# RK3399-M0 register map
File version: 1
CPU: CM0 r0p1, little endian, no MPU, no FPU, 4 interrupt priority bits, 32 interrupts
Registers are 32-bit, read-write, reset 0x0 unless marked. A register's access mark holds for its fields unless they carry their own. Offsets are from the block's base; [hi:lo] are bit positions; {n}, {i} and the like mark numbered series.

## MSCH0
Base 0x47A84000
Same registers: MSCH1 0x47A8C000
0x00 MSCH_Id_CoreId access not given reset 0xD867004 — Core ID register
0x04 MSCH_Id_RevisionId access not given reset 0x1AA00 — Revision ID register
0x08 MSCH_DeviceConf access not given — ddr configuration pointers
0x0C MSCH_DeviceSize access not given — ddr configuration sizes.
0x10 MSCH_DdrTimingA0 access not given reset 0x28140916 — DdrTimingA bank 0
0x14 MSCH_DdrTimingB0 access not given reset 0x40702 — DdrTimingB bank 0
0x18 MSCH_DdrTimingC0 access not given reset 0x2 — DdrTimingC bank 0
0x1C MSCH_DevToDev0 access not given reset 0x222 — Timing values concerning device to device data bus ownership c
0x110 MSCH_DdrMode access not given reset 0x4C — ddr mode definition.
0x1000 MSCH_AgingX0 access not given — Aging threshold multiplicator.

## SARADC
Base 0x47100000
0x00 SARADC_DATA ro — This register contains the data after A/D Conversion.
  [9:0] ADC_DATA — A/D value of the last conversion (DOUT[9:0]).
0x04 SARADC_STAS ro — The status register of A/D Converter.
  [0] ADC_STATUS — ADC status (EOC) 0: ADC stop 1: Conversion in progress
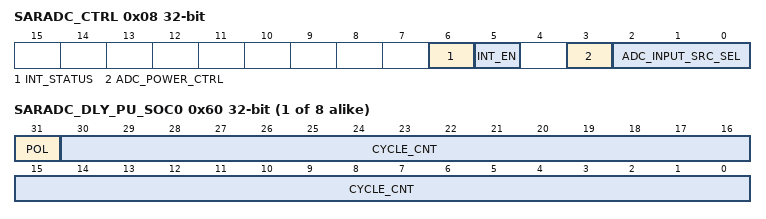
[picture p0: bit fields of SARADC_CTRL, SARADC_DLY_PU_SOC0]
0x08 SARADC_CTRL — The control register of A/D Converter.
  [6] INT_STATUS — Interrupt status. This bit will be set to 1 when end-of-conversion. Set 0 to clear the interrupt.
  [5] INT_EN — Interrupt enable. 0: Disable 1: Enable
  [3] ADC_POWER_CTRL — ADC power down control bit 0: ADC power down; 1: ADC power up and reset. start signal will be asserted (DLY_PU_SOC + 2) sclk clock period later after power up
  [2:0] ADC_INPUT_SRC_SEL — ADC input source selection(CH_SEL[2:0]). 000 : Input source 0 (SARADC_AIN[0]) 001 : Input source 1 (SARADC_AIN[1]) 010 : Input source 2 (SARADC_AIN[2]) 011 : Input source 3 (SARADC_AIN[3]) 100 : Input source 4 (SARADC_AIN[4]) 101 : Input source 5 (SARADC_AIN[5]) Others : Reserved
0x0C SARADC_DLY_PU_SOC — delay between power up and start command
  [5:0] DLY_PU_SOC — delay between power up and start command The start signal will be asserted (DLY_PU_SOC + 2) sclk clock period later after power up
{0x60+4i} SARADC_DLY_PU_SOC{i} access per field (i=0..7) — FIFO Register
  [31] POL rw — Polarity This bit indicates the polarity of the lower 31-bit counter. 0: Low 1: High
  [30:0] CYCLE_CNT ro — High/Low Cycle Counter This 31-bit counter indicates the effective cycles of high/low waveform.

## ISP0_MMU0
Base 0x47914000
Same registers: IEP_MMU 0x47670800, VOPL_MMU 0x478F0300, VOPB_MMU 0x47900300, ISP0_MMU1 0x47915000, ISP1_MMU0 0x47924000, ISP1_MMU1 0x47925000, HDCP_MMU 0x47930000
0x00 MMU_DTE_ADDR — MMU current page table address
  [31:0] MMU_DTE_ADDR — page table address
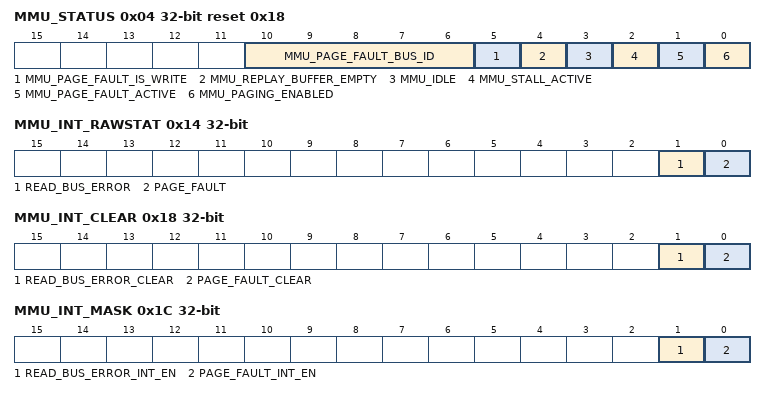
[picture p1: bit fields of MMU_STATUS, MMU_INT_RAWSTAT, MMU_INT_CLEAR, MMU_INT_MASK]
0x04 MMU_STATUS ro reset 0x18
  [10:6] MMU_PAGE_FAULT_BUS_ID — Index of master responsible for the last page fault
  [5] MMU_PAGE_FAULT_IS_WRITE — The direction of access for last page fault: 0: read 1:write
  [4] MMU_REPLAY_BUFFER_EMPTY — 1：The MMU replay buffer is empty.
  [3] MMU_IDLE — the MMu is idle when accesses are being translated and there are no unfinished translated access. The MMU_IDLE signal only reports idle when the MMU processor is idle and accesses are active on the external bus. Note: the MMU can be idle in page fault mode. 1: MMU is idle
  [2] MMU_STALL_ACTIVE — MMU stall mode currently enabled. The mode is enabled by command. 1: MMU is in stall active status
  [1] MMU_PAGE_FAULT_ACTIVE — MMU page fault mode currently enabled.The mode is enabled by command 1: page fault is active
  [0] MMU_PAGING_ENABLED — 0: paging is disabled 1: Paging is enabled
0x08 MMU_CMD — MMU command register
  [2:0] MMU_CMD — 0: MMU_ENABLE_PAGING. enable paging. 1: MMU_DISABLE_PAGING. disable paging. 2: MMU_ENABLE_STALL. turn on stall mode. 3: MMU_DISABLE_STALL. turn off stall mode. 4: MMU_ZAP_CACHE. zap the entire page table cache. 5: MMU_PAGE_FAULT_DONE. leave page fault mode. 6: MMU_FORCE_RESET. reset the mmu. The MMU_ENABLE_STALL command can always be issued. Other commands are ignored unless the MMU is idle or stalled.
0x0C MMU_PAGE_FAULT_ADDR ro — MMU logic address of last page fault register
  [31:0] MMU_PAGE_FAULT_ADDR — address of last page fault
0x10 MMU_ZAP_ONE_LINE — MMU zap cache line register
  [31:0] MMU_ZAP_ONE_LINE — address to be invalidated from the page table cache.
0x14 MMU_INT_RAWSTAT ro — MMU raw interrupt status register
  [1] READ_BUS_ERROR, [0] PAGE_FAULT
0x18 MMU_INT_CLEAR — MMU interrupt clear register
  [1] READ_BUS_ERROR_CLEAR — read bus error interrupt clear. write 1 to this register can clear read bus error interrupt.
  [0] PAGE_FAULT_CLEAR — page fault interrupt clear, write 1 to this register can clear page fault interrupt.
0x1C MMU_INT_MASK — MMU interrupt mask register
  [1] READ_BUS_ERROR_INT_EN — read bus error interrupt enable
  [0] PAGE_FAULT_INT_EN — page fault interrupt enable
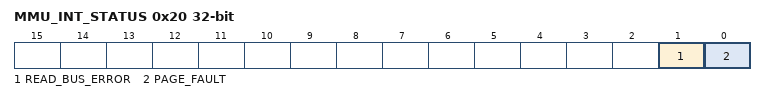
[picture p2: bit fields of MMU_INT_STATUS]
0x20 MMU_INT_STATUS access per field — MMU interrupt status register
  [1] READ_BUS_ERROR rw — read bus error interrupt
  [0] PAGE_FAULT ro — page fault interrupt
0x24 MMU_AUTO_GATING — clock atuo gating register
  [0] MMU_ATUO_GATING — mmu clock auto gating when it is 1, the mmu will auto gating itself
